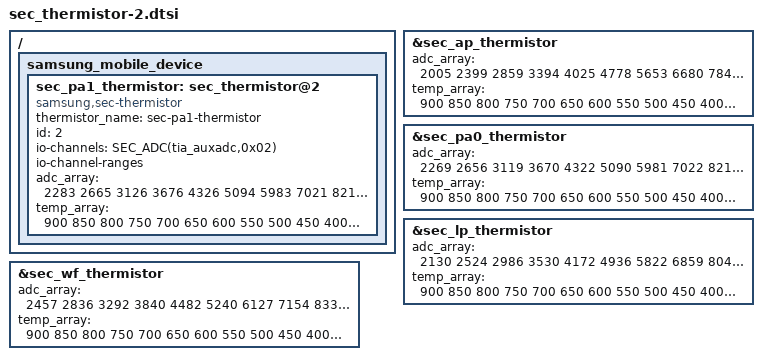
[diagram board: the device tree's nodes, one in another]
/ {
	fragment@smd {
		target-path = "/";
		__overlay__ {
			samsung_mobile_device {
				sec_pa1_thermistor: sec_thermistor@2 {
					compatible = "samsung,sec-thermistor";
					status = "okay";
					thermistor_name = "sec-pa1-thermistor";
					id = <2>;

					io-channels = SEC_ADC(tia_auxadc,0x02);
					io-channel-names = "pa1_therm";
					io-channel-ranges;
				};
			};
		};
	};
};

/* /home/dpi/qb5_8814/workspace/P4_1716/android/kernel/kmodule/sec_pm/sec_thermistor/dts/sec_thermistor_mtk.gts10u.dtsi */
&sec_ap_thermistor {
	adc_array = <2005 2399 2859 3394 4025 4778 5653 6680 7844 9175
				10686 12315 14090 15964 17918 19880 21798 23735 25329 26761
				28005 29077 29947>;

	temp_array = <900 850 800 750 700 650 600 550 500 450
				400 350 300 250 200 150 100 50 0 (-50)
				(-100) (-150) (-200)>;
};

&sec_pa0_thermistor {
	adc_array = <2269 2656 3119 3670 4322 5090 5981 7022 8212 9576
				11096 12751 14537 16410 18345 20317 22245 24098 25695 27107
				28310 29322 30142>;

	temp_array = <900 850 800 750 700 650 600 550 500 450
				400 350 300 250 200 150 100 50 0 (-50)
				(-100) (-150) (-200)>;
};

&sec_pa1_thermistor {
	adc_array = <2283 2665 3126 3676 4326 5094 5983 7021 8211 9573
				11092 12754 14540 16432 18367 20319 22222 24094 25639 27052
				28263 29282 30109>;

	temp_array = <900 850 800 750 700 650 600 550 500 450
				400 350 300 250 200 150 100 50 0 (-50)
				(-100) (-150) (-200)>;
};

&sec_lp_thermistor {
	adc_array = <2130 2524 2986 3530 4172 4936 5822 6859 8040 9394
				10903 12548 14329 16210 18150 20116 22029 23948 25519 26933
				28164 29210 30065>;

	temp_array = <900 850 800 750 700 650 600 550 500 450
				400 350 300 250 200 150 100 50 0 (-50)
				(-100) (-150) (-200)>;
};

&sec_wf_thermistor {
	adc_array = <2457 2836 3292 3840 4482 5240 6127 7154 8339 9694
				11194 12843 14618 16481 18409 20377 22306 24158 25755 27173
				28381 29391 30215>;

	temp_array = <900 850 800 750 700 650 600 550 500 450
				400 350 300 250 200 150 100 50 0 (-50)
				(-100) (-150) (-200)>;
};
